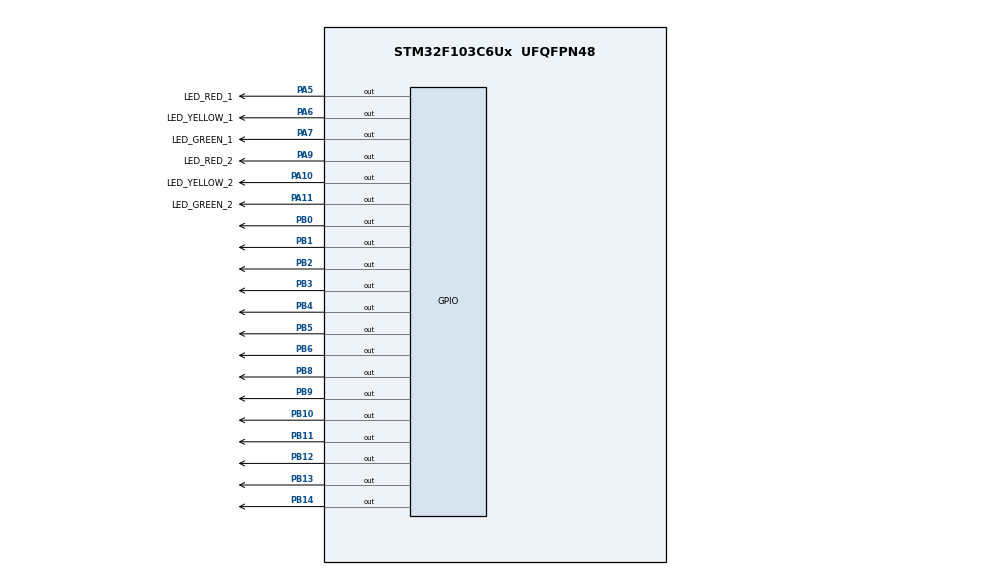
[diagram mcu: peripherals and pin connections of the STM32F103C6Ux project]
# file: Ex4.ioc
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Mcu.Family=STM32F1
Mcu.Name=STM32F103C6Ux
Mcu.Package=UFQFPN48
NVIC.PriorityGroup=NVIC_PRIORITYGROUP_4
PA10.GPIO_Label=LED_YELLOW_2
PA10.Signal=GPIO_Output
PA11.GPIO_Label=LED_GREEN_2
PA11.Signal=GPIO_Output
PA5.GPIO_Label=LED_RED_1
PA5.Signal=GPIO_Output
PA6.GPIO_Label=LED_YELLOW_1
PA6.Signal=GPIO_Output
PA7.GPIO_Label=LED_GREEN_1
PA7.Signal=GPIO_Output
PA9.GPIO_Label=LED_RED_2
PA9.Signal=GPIO_Output
PB0.Signal=GPIO_Output
PB1.Signal=GPIO_Output
PB10.Signal=GPIO_Output
PB11.Signal=GPIO_Output
PB12.Signal=GPIO_Output
PB13.Signal=GPIO_Output
PB14.Signal=GPIO_Output
PB2.Signal=GPIO_Output
PB3.Signal=GPIO_Output
PB4.Signal=GPIO_Output
PB5.Signal=GPIO_Output
PB6.Signal=GPIO_Output
PB8.Signal=GPIO_Output
PB9.Signal=GPIO_Output
ProjectManager.HeapSize=0x200
ProjectManager.StackSize=0x400
ProjectManager.TargetToolchain=STM32CubeIDE
RCC.APB1Freq_Value=8000000
RCC.APB2Freq_Value=8000000
VP_SYS_VS_ND.Mode=No_Debug
board=custom

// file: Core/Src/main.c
/* USER CODE BEGIN Header */
/**
  ******************************************************************************
  * @file           : main.c
  * @brief          : Main program body
  ******************************************************************************
  * @attention
  *
  * <h2><center>&copy; Copyright (c) 2022 STMicroelectronics.
  * All rights reserved.</center></h2>
  *
  * This software component is licensed by ST under BSD 3-Clause license,
  * the "License"; You may not use this file except in compliance with the
  * License. You may obtain a copy of the License at:
  *                        opensource.org/licenses/BSD-3-Clause
  *
  ******************************************************************************
  */
/* USER CODE END Header */
#include "main.h"

void SystemClock_Config(void);
static void MX_GPIO_Init(void);

/*
 * @brief	Display 7-Segment LED on selected block of data port bit
 *
 * @note	This function uses GPIOx_ODR to write to write the desired output.
 * 			It also assumes that all pins for display 7-segment LED is on only 1 port (A, B or C).
 * 			They are placed adjacently start from <start_index>
 *
 * 			|> Supernote: using bit mask at when access + write GPIOx->ODR can decrease
 * 			accidentally changing other pin when manipulating with selected block of port bit.
 * 			However, some bugs may occur incidentally. So be careful when using this function. *
 *
 * @param	start_index: the first index of selected block
 * 			Example: if start_index = 0, GPIOA => 7-Segment LED GPIOA[0:6]
 *
 * @param 	num: 0->9
 *
 * @param   GPIOx: Selected port
 * */
void display7SEG(int num, GPIO_TypeDef* GPIOx, uint16_t start_index){
	__IO uint16_t temp;
	switch(num){
	case 0:
		temp = 0b1000000;
		break;
	case 1:
		temp = 0b1111001;
		break;
	case 2:
		temp = 0b0100100;
		break;
	case 3:
		temp = 0b0110000;
		break;
	case 4:
		temp = 0b0011001;
		break;
	case 5:
		temp = 0b0010010;
		break;
	case 6:
		temp = 0b0000010;
		break;
	case 7:
		temp = 0b1111000;
		break;
	case 8:
		temp = 0b0;
		break;
	case 9:
		temp = 0b0010000;
		break;
	default:
		temp = !0b0;
		break;
	}
	uint16_t bitmask = 0b1111111 << start_index ;
	GPIOx->ODR = (GPIOx->ODR & ~bitmask) | (temp << start_index);
}
int main(void)
{

  /* MCU Configuration--------------------------------------------------------*/

  /* Reset of all peripherals, Initializes the Flash interface and the Systick. */
  HAL_Init();

  /* Configure the system clock */
  SystemClock_Config();

  /* Initialize all configured peripherals */
  MX_GPIO_Init();

  /* Infinite loop */
  /* USER CODE BEGIN WHILE */
  int counter = 0;
  while (1)
  {
      if(counter >= 10) counter = 0;
      /* This code is test
       * - the synchronization of 2 display7SEG on 1 counter
       * - the mixer 2 display7SEG on only 1 port
      */
      display7SEG(9 - counter, GPIOB, 8);
      display7SEG(counter, GPIOB, 0);
      counter++;
      HAL_Delay(1000);
  }
    /* USER CODE END WHILE */

}

void SystemClock_Config(void)
{
  RCC_OscInitTypeDef RCC_OscInitStruct = {0};
  RCC_ClkInitTypeDef RCC_ClkInitStruct = {0};

  /** Initializes the RCC Oscillators according to the specified parameters
  * in the RCC_OscInitTypeDef structure.
  */
  RCC_OscInitStruct.OscillatorType = RCC_OSCILLATORTYPE_HSI;
  RCC_OscInitStruct.HSIState = RCC_HSI_ON;
  RCC_OscInitStruct.HSICalibrationValue = RCC_HSICALIBRATION_DEFAULT;
  RCC_OscInitStruct.PLL.PLLState = RCC_PLL_NONE;
  if (HAL_RCC_OscConfig(&RCC_OscInitStruct) != HAL_OK)
  {
    Error_Handler();
  }
  /** Initializes the CPU, AHB and APB buses clocks
  */
  RCC_ClkInitStruct.ClockType = RCC_CLOCKTYPE_HCLK|RCC_CLOCKTYPE_SYSCLK
                              |RCC_CLOCKTYPE_PCLK1|RCC_CLOCKTYPE_PCLK2;
  RCC_ClkInitStruct.SYSCLKSource = RCC_SYSCLKSOURCE_HSI;
  RCC_ClkInitStruct.AHBCLKDivider = RCC_SYSCLK_DIV1;
  RCC_ClkInitStruct.APB1CLKDivider = RCC_HCLK_DIV1;
  RCC_ClkInitStruct.APB2CLKDivider = RCC_HCLK_DIV1;

  if (HAL_RCC_ClockConfig(&RCC_ClkInitStruct, FLASH_LATENCY_0) != HAL_OK)
  {
    Error_Handler();
  }
}

static void MX_GPIO_Init(void)
{
  GPIO_InitTypeDef GPIO_InitStruct = {0};

  /* GPIO Ports Clock Enable */
  __HAL_RCC_GPIOA_CLK_ENABLE();
  __HAL_RCC_GPIOB_CLK_ENABLE();

  /*Configure GPIO pin Output Level */
  HAL_GPIO_WritePin(GPIOA, LED_RED_1_Pin|LED_YELLOW_1_Pin|LED_GREEN_1_Pin|LED_RED_2_Pin
                          |LED_YELLOW_2_Pin|LED_GREEN_2_Pin, GPIO_PIN_RESET);

  /*Configure GPIO pin Output Level */
  HAL_GPIO_WritePin(GPIOB, GPIO_PIN_0|GPIO_PIN_1|GPIO_PIN_2|GPIO_PIN_10
                          |GPIO_PIN_11|GPIO_PIN_12|GPIO_PIN_13|GPIO_PIN_14
                          |GPIO_PIN_3|GPIO_PIN_4|GPIO_PIN_5|GPIO_PIN_6
                          |GPIO_PIN_8|GPIO_PIN_9, GPIO_PIN_RESET);

  /*Configure GPIO pins : LED_RED_1_Pin LED_YELLOW_1_Pin LED_GREEN_1_Pin LED_RED_2_Pin
                           LED_YELLOW_2_Pin LED_GREEN_2_Pin */
  GPIO_InitStruct.Pin = LED_RED_1_Pin|LED_YELLOW_1_Pin|LED_GREEN_1_Pin|LED_RED_2_Pin
                          |LED_YELLOW_2_Pin|LED_GREEN_2_Pin;
  GPIO_InitStruct.Mode = GPIO_MODE_OUTPUT_PP;
  GPIO_InitStruct.Pull = GPIO_NOPULL;
  GPIO_InitStruct.Speed = GPIO_SPEED_FREQ_LOW;
  HAL_GPIO_Init(GPIOA, &GPIO_InitStruct);

  /*Configure GPIO pins : PB0 PB1 PB2 PB10
                           PB11 PB12 PB13 PB14
                           PB3 PB4 PB5 PB6
                           PB8 PB9 */
  GPIO_InitStruct.Pin = GPIO_PIN_0|GPIO_PIN_1|GPIO_PIN_2|GPIO_PIN_10
                          |GPIO_PIN_11|GPIO_PIN_12|GPIO_PIN_13|GPIO_PIN_14
                          |GPIO_PIN_3|GPIO_PIN_4|GPIO_PIN_5|GPIO_PIN_6
                          |GPIO_PIN_8|GPIO_PIN_9;
  GPIO_InitStruct.Mode = GPIO_MODE_OUTPUT_PP;
  GPIO_InitStruct.Pull = GPIO_NOPULL;
  GPIO_InitStruct.Speed = GPIO_SPEED_FREQ_LOW;
  HAL_GPIO_Init(GPIOB, &GPIO_InitStruct);

}

void Error_Handler(void)
{
  __disable_irq();
  while (1)
  {
  }
}

/************************ (C) COPYRIGHT STMicroelectronics *****END OF FILE****/
